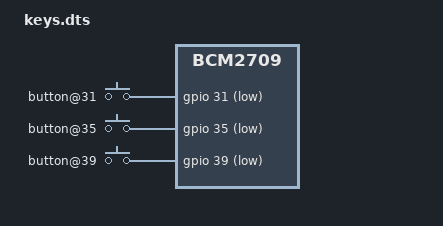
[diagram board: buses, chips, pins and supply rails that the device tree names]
   /dts-v1/;
    /plugin/;
    / {
       compatible = "brcm,bcm2835", "brcm,bcm2708", "brcm,bcm2709";
       
       fragment@0 {
          target-path = "/";
          __overlay__ {
             keypad: keys {
                compatible = "gpio-keys";
                #address-cells = <1>;
                #size-cells = <0>;
                button@31 {
                   linux,code = <1>;
                   gpios = <&gpio 31 1>;
                };
                button@35 {
                   linux,code = <2>;
                   gpios = <&gpio 35 1>;
                };
                button@39 {
                   linux,code = <3>;
                   gpios = <&gpio 39 1>;
                };
             };
          };
       };
    };
